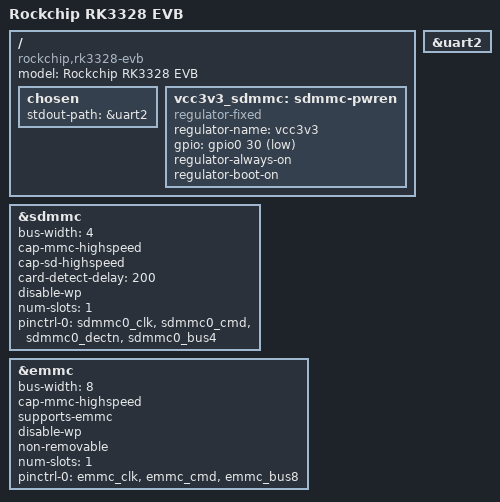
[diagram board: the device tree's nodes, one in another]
/*
 * (C) Copyright 2016 Rockchip Electronics Co., Ltd
 *
 * SPDX-License-Identifier:     GPL-2.0+
 */

/dts-v1/;
#include "rk3328.dtsi"

/ {
	model = "Rockchip RK3328 EVB";
	compatible = "rockchip,rk3328-evb", "rockchip,rk3328";

	chosen {
		stdout-path = &uart2;
	};

	vcc3v3_sdmmc: sdmmc-pwren {
		compatible = "regulator-fixed";
		regulator-name = "vcc3v3";
		gpio = <&gpio0 30 GPIO_ACTIVE_LOW>;
		regulator-always-on;
		regulator-boot-on;
	};
};

&uart2 {
	status = "okay";
};

&sdmmc {
	bus-width = <4>;
	cap-mmc-highspeed;
	cap-sd-highspeed;
	card-detect-delay = <200>;
	disable-wp;
	num-slots = <1>;
	pinctrl-names = "default";
	pinctrl-0 = <&sdmmc0_clk>, <&sdmmc0_cmd>, <&sdmmc0_dectn>, <&sdmmc0_bus4>;
	status = "okay";
};

&emmc {
	bus-width = <8>;
	cap-mmc-highspeed;
	supports-emmc;
	disable-wp;
	non-removable;
	num-slots = <1>;
	pinctrl-names = "default";
	pinctrl-0 = <&emmc_clk &emmc_cmd &emmc_bus8>;
	status = "okay";
};
